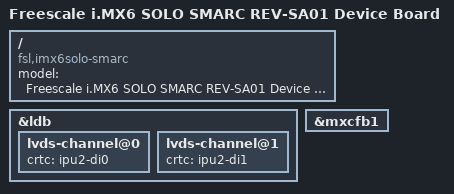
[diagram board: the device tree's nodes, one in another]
/dts-v1/;

#include "imx6dl.dtsi"
#include "imx6qdl-smarc.dtsi"
#include "imx6qdl-rev-sa01-pfuze100.dtsi"

/ {
	model = "Freescale i.MX6 SOLO SMARC REV-SA01 Device Board";
	compatible = "fsl,imx6solo-smarc", "fsl,imx6q";
};

&ldb {
	lvds-channel@0 {
		crtc = "ipu2-di0";
	};

	lvds-channel@1 {
		crtc = "ipu2-di1";
	};
};

&mxcfb1 {
	status = "okay";
};

